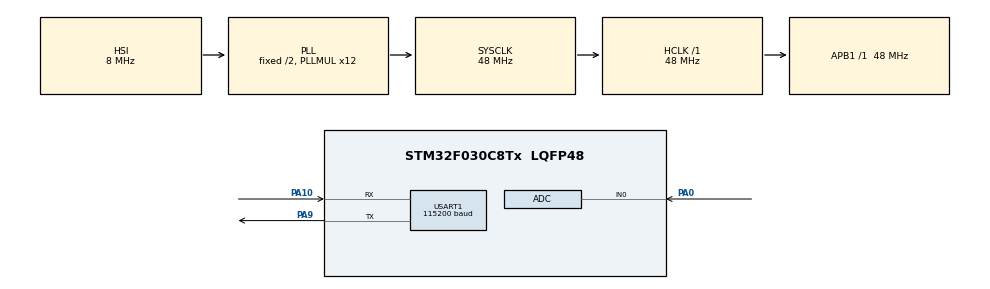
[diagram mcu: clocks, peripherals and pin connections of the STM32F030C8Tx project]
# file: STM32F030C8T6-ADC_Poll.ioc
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ADC.ClockPrescaler=ADC_CLOCK_SYNC_PCLK_DIV4
ADC.SamplingTime=ADC_SAMPLETIME_239CYCLES_5
Mcu.Family=STM32F0
Mcu.Name=STM32F030C8Tx
Mcu.Package=LQFP48
PA0.Mode=IN0
PA0.Signal=ADC_IN0
PA10.Mode=Asynchronous
PA10.Signal=USART1_RX
PA9.Mode=Asynchronous
PA9.Signal=USART1_TX
ProjectManager.TargetToolchain=MDK-ARM V5
RCC.AHBFreq_Value=48000000
RCC.APB1Freq_Value=48000000
RCC.APB1TimFreq_Value=48000000
RCC.HCLKFreq_Value=48000000
RCC.PLLMUL=RCC_PLL_MUL12
RCC.SYSCLKFreq_VALUE=48000000
RCC.SYSCLKSource=RCC_SYSCLKSOURCE_PLLCLK
USART1.BaudRate=115200
board=STM32F030C8T6-ADC_Poll

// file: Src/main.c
/**
  ******************************************************************************
  * File Name          : main.c
  * Description        : Main program body
  ******************************************************************************
  *
  * COPYRIGHT(c) 2015 STMicroelectronics
  *
  * Redistribution and use in source and binary forms, with or without modification,
  * are permitted provided that the following conditions are met:
  *   1. Redistributions of source code must retain the above copyright notice,
  *      this list of conditions and the following disclaimer.
  *   2. Redistributions in binary form must reproduce the above copyright notice,
  *      this list of conditions and the following disclaimer in the documentation
  *      and/or other materials provided with the distribution.
  *   3. Neither the name of STMicroelectronics nor the names of its contributors
  *      may be used to endorse or promote products derived from this software
  *      without specific prior written permission.
  *
  * THIS SOFTWARE IS PROVIDED BY THE COPYRIGHT HOLDERS AND CONTRIBUTORS "AS IS"
  * AND ANY EXPRESS OR IMPLIED WARRANTIES, INCLUDING, BUT NOT LIMITED TO, THE
  * IMPLIED WARRANTIES OF MERCHANTABILITY AND FITNESS FOR A PARTICULAR PURPOSE ARE
  * DISCLAIMED. IN NO EVENT SHALL THE COPYRIGHT HOLDER OR CONTRIBUTORS BE LIABLE
  * FOR ANY DIRECT, INDIRECT, INCIDENTAL, SPECIAL, EXEMPLARY, OR CONSEQUENTIAL
  * DAMAGES (INCLUDING, BUT NOT LIMITED TO, PROCUREMENT OF SUBSTITUTE GOODS OR
  * SERVICES; LOSS OF USE, DATA, OR PROFITS; OR BUSINESS INTERRUPTION) HOWEVER
  * CAUSED AND ON ANY THEORY OF LIABILITY, WHETHER IN CONTRACT, STRICT LIABILITY,
  * OR TORT (INCLUDING NEGLIGENCE OR OTHERWISE) ARISING IN ANY WAY OUT OF THE USE
  * OF THIS SOFTWARE, EVEN IF ADVISED OF THE POSSIBILITY OF SUCH DAMAGE.
  *
  ******************************************************************************
  */
#include "stm32f0xx_hal.h"
#include "adc.h"
#include "usart.h"
#include "gpio.h"

/* USER CODE BEGIN Includes */
#include "stdio.h"
#ifdef __GNUC__
#define PUTCHAR_PROTOTYPE int __io_putchar(int ch)
#else
#define PUTCHAR_PROTOTYPE int fputc(int ch, FILE *f)
#endif
PUTCHAR_PROTOTYPE
{
HAL_UART_Transmit(&huart1 , (uint8_t *)&ch, 1, 0xFFFF);
return ch;
}
/* USER CODE END Includes */

/* USER CODE BEGIN PV */
/* Private variables ---------------------------------------------------------*/

/* USER CODE END PV */

void SystemClock_Config(void);

/* USER CODE BEGIN PFP */
/* Private function prototypes -----------------------------------------------*/

/* USER CODE END PFP */
unsigned long shijian=0;
uint16_t ADCValue = 0;

int main(void)
{

  /* MCU Configuration----------------------------------------------------------*/

  /* Reset of all peripherals, Initializes the Flash interface and the Systick. */
  HAL_Init();

  /* Configure the system clock */
  SystemClock_Config();

  /* Initialize all configured peripherals */
  MX_GPIO_Init();
  MX_ADC_Init();
  MX_USART1_UART_Init();

  /* USER CODE BEGIN 2 */
	shijian=HAL_GetTick();
  /* USER CODE END 2 */

  /* Infinite loop */
  while (1)
  {

  /* USER CODE BEGIN 3 */
	if(	HAL_GetTick()-shijian>=500)
			{
	if (HAL_ADC_Start(&hadc) != HAL_OK)
  {
		printf("HAL_Start_Error...\r");
  }

  if (HAL_ADC_PollForConversion(&hadc, 10) != HAL_OK)
  {
		printf("HAL_ADC_PollForConversion_Error...\r");
  }
  else
  {
    ADCValue = HAL_ADC_GetValue(&hadc);
		printf("ADCValue=%d\r",ADCValue);
		float VccPa0=0.00;
		VccPa0=ADCValue*(3.3/4095);
		printf("VccPa0=%0.fV\r",VccPa0);

  }
	shijian=HAL_GetTick();
	}

  }
  /* USER CODE END 3 */

}

/** System Clock Configuration
*/
void SystemClock_Config(void)
{

  RCC_OscInitTypeDef RCC_OscInitStruct;
  RCC_ClkInitTypeDef RCC_ClkInitStruct;
  RCC_PeriphCLKInitTypeDef PeriphClkInit;

  RCC_OscInitStruct.OscillatorType = RCC_OSCILLATORTYPE_HSI;
  RCC_OscInitStruct.HSIState = RCC_HSI_ON;
  RCC_OscInitStruct.HSICalibrationValue = 16;
  RCC_OscInitStruct.PLL.PLLState = RCC_PLL_ON;
  RCC_OscInitStruct.PLL.PLLSource = RCC_PLLSOURCE_HSI;
  RCC_OscInitStruct.PLL.PLLMUL = RCC_PLL_MUL12;
  RCC_OscInitStruct.PLL.PREDIV = RCC_PREDIV_DIV1;
  HAL_RCC_OscConfig(&RCC_OscInitStruct);

  RCC_ClkInitStruct.ClockType = RCC_CLOCKTYPE_SYSCLK;
  RCC_ClkInitStruct.SYSCLKSource = RCC_SYSCLKSOURCE_PLLCLK;
  RCC_ClkInitStruct.AHBCLKDivider = RCC_SYSCLK_DIV1;
  RCC_ClkInitStruct.APB1CLKDivider = RCC_HCLK_DIV1;
  HAL_RCC_ClockConfig(&RCC_ClkInitStruct, FLASH_LATENCY_1);

  PeriphClkInit.PeriphClockSelection = RCC_PERIPHCLK_USART1;
  PeriphClkInit.Usart1ClockSelection = RCC_USART1CLKSOURCE_PCLK1;
  HAL_RCCEx_PeriphCLKConfig(&PeriphClkInit);

  HAL_SYSTICK_Config(HAL_RCC_GetHCLKFreq()/1000);

  HAL_SYSTICK_CLKSourceConfig(SYSTICK_CLKSOURCE_HCLK);

  /* SysTick_IRQn interrupt configuration */
  HAL_NVIC_SetPriority(SysTick_IRQn, 0, 0);
}

/************************ (C) COPYRIGHT STMicroelectronics *****END OF FILE****/
